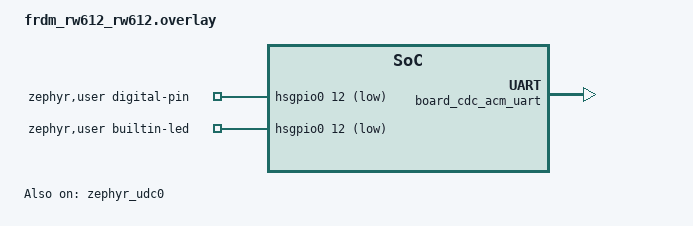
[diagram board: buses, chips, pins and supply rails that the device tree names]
/*
 * Copyright (c) Arduino s.r.l. and/or its affiliated companies
 *
 * SPDX-License-Identifier: Apache-2.0
 */

&zephyr_udc0 {
	status = "okay";
	board_cdc_acm_uart: board_cdc_acm_uart {
		compatible = "zephyr,cdc-acm-uart";
		status = "okay";
	};
};

/* Shared with the MCUboot image; see the header comment there. */
#include "frdm_rw612_rw612-partitions.dtsi"

/ {
	zephyr,user {
		digital-pin-gpios = <&hsgpio0 12 GPIO_ACTIVE_LOW>;
		builtin-led-gpios = <&hsgpio0 12 GPIO_ACTIVE_LOW>;
		cdc-acm-serial = <&board_cdc_acm_uart>; /* 'Serial' object is managed by SerialUSB */
		i2cs = <&arduino_i2c>;
		spis = <&flexcomm1>;
	};
};
